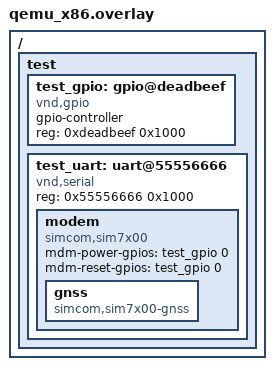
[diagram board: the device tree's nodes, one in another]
/ {
	test {
		#address-cells = <1>;
		#size-cells = <1>;

		test_gpio: gpio@deadbeef {
			compatible = "vnd,gpio";
			gpio-controller;
			reg = <0xdeadbeef 0x1000>;
			#gpio-cells = <2>;
			status = "okay";
		};

		test_uart: uart@55556666 {
			compatible = "vnd,serial";
			reg = <0x55556666 0x1000>;
			status = "okay";

			modem {
				compatible = "simcom,sim7x00";
				status = "okay";
				mdm-power-gpios = <&test_gpio 0 0>;
				mdm-reset-gpios = <&test_gpio 0 0>;

				gnss {
					compatible = "simcom,sim7x00-gnss";
					status = "okay";
				};
			};
		};
	};
};
